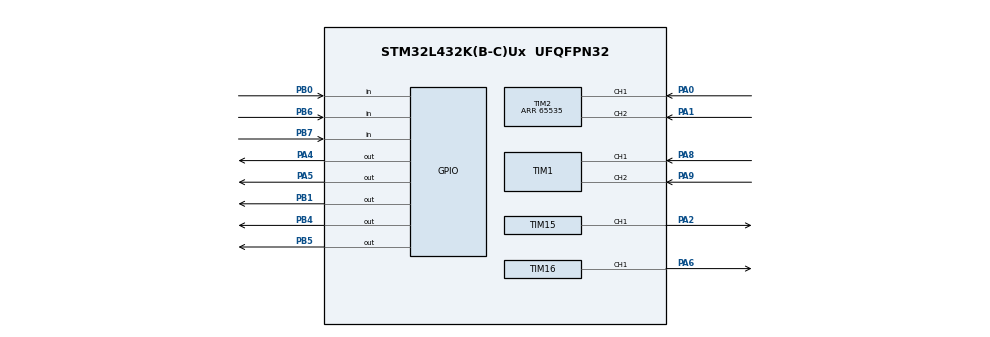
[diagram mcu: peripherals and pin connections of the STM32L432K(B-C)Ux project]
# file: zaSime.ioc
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Mcu.Family=STM32L4
Mcu.Name=STM32L432K(B-C)Ux
Mcu.Package=UFQFPN32
NVIC.PriorityGroup=NVIC_PRIORITYGROUP_4
NVIC.TIM6_DAC_IRQn=true\:0\:0\:false\:false\:true\:true\:true\:true
PA0.Signal=S_TIM2_CH1
PA1.Signal=S_TIM2_CH2
PA2.Signal=S_TIM15_CH1
PA4.Signal=GPIO_Output
PA5.Signal=GPIO_Output
PA6.Signal=S_TIM16_CH1
PA8.Signal=S_TIM1_CH1
PA9.Signal=S_TIM1_CH2
PB0.Signal=GPIO_Input
PB1.Signal=GPIO_Output
PB4\ (NJTRST).Signal=GPIO_Output
PB5.Signal=GPIO_Output
PB6.Signal=GPIO_Input
PB7.Signal=GPIO_Input
ProjectManager.HeapSize=0x200
ProjectManager.StackSize=0x400
ProjectManager.TargetToolchain=STM32CubeIDE
RCC.ADCFreq_Value=64000000
RCC.AHBFreq_Value=80000000
RCC.APB1Freq_Value=80000000
RCC.APB1TimFreq_Value=80000000
RCC.APB2Freq_Value=80000000
RCC.APB2TimFreq_Value=80000000
RCC.CortexFreq_Value=80000000
RCC.HCLKFreq_Value=80000000
RCC.HSE_VALUE=8000000
RCC.HSI48_VALUE=48000000
RCC.HSI_VALUE=16000000
RCC.LSE_VALUE=32768
RCC.MSI_VALUE=4000000
RCC.PLLN=10
RCC.PLLSourceVirtual=RCC_PLLSOURCE_HSI
RCC.SYSCLKFreq_VALUE=80000000
RCC.SYSCLKSource=RCC_SYSCLKSOURCE_PLLCLK
RCC.USBFreq_Value=64000000
RCC.VCOOutputFreq_Value=160000000
SH.S_TIM15_CH1.0=TIM15_CH1,PWM Generation1 CH1
SH.S_TIM16_CH1.0=TIM16_CH1,PWM Generation1 CH1
SH.S_TIM1_CH1.0=TIM1_CH1,Encoder_Interface
SH.S_TIM1_CH2.0=TIM1_CH2,Encoder_Interface
SH.S_TIM2_CH1.0=TIM2_CH1,Encoder_Interface
SH.S_TIM2_CH2.0=TIM2_CH2,Encoder_Interface
TIM1.EncoderMode=TIM_ENCODERMODE_TI12
TIM15.AutoReloadPreload=TIM_AUTORELOAD_PRELOAD_ENABLE
TIM15.Channel-PWM\ Generation1\ CH1=TIM_CHANNEL_1
TIM15.Period=4000-1
TIM15.Prescaler=0
TIM16.AutoReloadPreload=TIM_AUTORELOAD_PRELOAD_ENABLE
TIM16.Channel=TIM_CHANNEL_1
TIM16.Period=4000-1
TIM16.Prescaler=0
TIM2.EncoderMode=TIM_ENCODERMODE_TI12
TIM2.Period=65535
TIM6.Period=999
TIM6.Prescaler=79
VP_TIM16_VS_ClockSourceINT.Mode=Enable_Timer
VP_TIM6_VS_ClockSourceINT.Mode=Enable_Timer
board=custom

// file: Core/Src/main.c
/* USER CODE BEGIN Header */
/**
  ******************************************************************************
  * @file           : main.c
  * @brief          : Main program body
  ******************************************************************************
  * @attention
  *
  * Copyright (c) 2025 STMicroelectronics.
  * All rights reserved.
  *
  * This software is licensed under terms that can be found in the LICENSE file
  * in the root directory of this software component.
  * If no LICENSE file comes with this software, it is provided AS-IS.
  *
  ******************************************************************************
  */
/* USER CODE END Header */
#include "main.h"
#include "tim.h"
#include "gpio.h"

/* USER CODE BEGIN Includes */
#include "../Lib/Motori/motori.h"
#include "../Lib/Odometrija/odometrija.h"
/* USER CODE END Includes */

void SystemClock_Config(void);

int main(void)
{

  /* MCU Configuration--------------------------------------------------------*/

  /* Reset of all peripherals, Initializes the Flash interface and the Systick. */
  HAL_Init();

  /* Configure the system clock */
  SystemClock_Config();

  /* Initialize all configured peripherals */
  MX_GPIO_Init();
  MX_TIM6_Init();
  MX_TIM1_Init();
  MX_TIM2_Init();
  MX_TIM15_Init();
  MX_TIM16_Init();
  /* USER CODE BEGIN 2 */
  LL_TIM_EnableCounter(TIM1);
  LL_TIM_EnableCounter(TIM2);
 LL_TIM_EnableIT_UPDATE(TIM6);
 LL_TIM_EnableCounter(TIM6);

// HAL_TIM_PWM_Start(&htim15, TIM_CHANNEL_1);
// TIM15->CCR1 = TIM15->ARR/2;
//
// HAL_TIM_PWM_Start(&htim16, TIM_CHANNEL_1);
//  TIM16->CCR1 = TIM16->ARR/2;

  odometrija_init();

  //motor1_init(1,70); //npr
  //motor2_init(1,70);
  /* USER CODE END 2 */

  /* Infinite loop */
  while (1)
  {

  }
}

void SystemClock_Config(void)
{
  LL_FLASH_SetLatency(LL_FLASH_LATENCY_4);
  while(LL_FLASH_GetLatency()!= LL_FLASH_LATENCY_4)
  {
  }
  LL_PWR_SetRegulVoltageScaling(LL_PWR_REGU_VOLTAGE_SCALE1);
  while (LL_PWR_IsActiveFlag_VOS() != 0)
  {
  }
  LL_RCC_HSI_Enable();

   /* Wait till HSI is ready */
  while(LL_RCC_HSI_IsReady() != 1)
  {

  }
  LL_RCC_HSI_SetCalibTrimming(16);
  LL_RCC_PLL_ConfigDomain_SYS(LL_RCC_PLLSOURCE_HSI, LL_RCC_PLLM_DIV_1, 10, LL_RCC_PLLR_DIV_2);
  LL_RCC_PLL_EnableDomain_SYS();
  LL_RCC_PLL_Enable();

   /* Wait till PLL is ready */
  while(LL_RCC_PLL_IsReady() != 1)
  {

  }
  LL_RCC_SetSysClkSource(LL_RCC_SYS_CLKSOURCE_PLL);

   /* Wait till System clock is ready */
  while(LL_RCC_GetSysClkSource() != LL_RCC_SYS_CLKSOURCE_STATUS_PLL)
  {

  }
  LL_RCC_SetAHBPrescaler(LL_RCC_SYSCLK_DIV_1);
  LL_RCC_SetAPB1Prescaler(LL_RCC_APB1_DIV_1);
  LL_RCC_SetAPB2Prescaler(LL_RCC_APB2_DIV_1);
  LL_SetSystemCoreClock(80000000);

   /* Update the time base */
  if (HAL_InitTick (TICK_INT_PRIORITY) != HAL_OK)
  {
    Error_Handler();
  }
}

void Error_Handler(void)
{
  __disable_irq();
  while (1)
  {
  }
}
